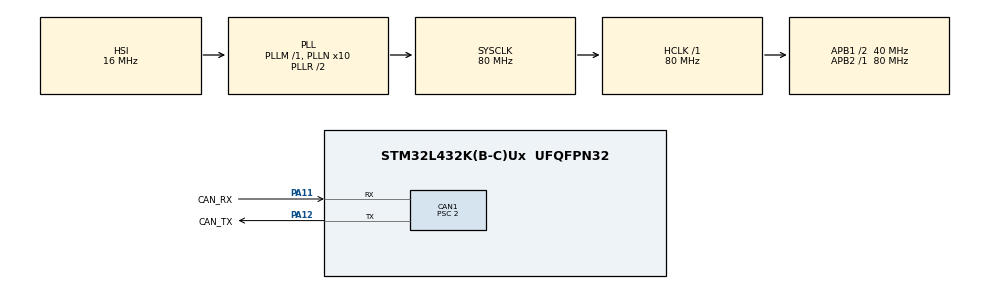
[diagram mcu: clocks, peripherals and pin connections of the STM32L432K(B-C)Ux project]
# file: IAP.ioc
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CAN1.BS1=CAN_BS1_15TQ
CAN1.BS2=CAN_BS2_4TQ
CAN1.CalculateTimeQuantum=50.0
CAN1.Prescaler=2
CAN1.SJW=CAN_SJW_4TQ
CAN1.TXFP=ENABLE
Mcu.Family=STM32L4
Mcu.Name=STM32L432K(B-C)Ux
Mcu.Package=UFQFPN32
NVIC.CAN1_RX0_IRQn=true\:0\:0\:false\:false\:true\:true\:true
NVIC.CAN1_TX_IRQn=true\:0\:0\:false\:false\:true\:true\:true
NVIC.PriorityGroup=NVIC_PRIORITYGROUP_4
PA11.GPIO_Label=CAN_RX
PA11.Mode=Master
PA11.Signal=CAN1_RX
PA12.GPIO_Label=CAN_TX
PA12.Mode=Master
PA12.Signal=CAN1_TX
ProjectManager.HeapSize=0x200
ProjectManager.StackSize=0x400
ProjectManager.TargetToolchain=EWARM V8
RCC.ADCFreq_Value=64000000
RCC.AHBFreq_Value=80000000
RCC.APB1CLKDivider=RCC_HCLK_DIV2
RCC.APB1Freq_Value=40000000
RCC.APB1TimFreq_Value=80000000
RCC.APB2Freq_Value=80000000
RCC.APB2TimFreq_Value=80000000
RCC.CortexFreq_Value=80000000
RCC.HCLKFreq_Value=80000000
RCC.HSE_VALUE=8000000
RCC.HSI48_VALUE=48000000
RCC.HSI_VALUE=16000000
RCC.LSE_VALUE=32768
RCC.MSI_VALUE=4000000
RCC.PLLN=10
RCC.PLLSourceVirtual=RCC_PLLSOURCE_HSI
RCC.SYSCLKFreq_VALUE=80000000
RCC.SYSCLKSource=RCC_SYSCLKSOURCE_PLLCLK
RCC.USBFreq_Value=64000000
RCC.VCOOutputFreq_Value=160000000
board=custom

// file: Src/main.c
/* USER CODE BEGIN Header */
/**
  ******************************************************************************
  * @file           : main.c
  * @brief          : Main program body
  ******************************************************************************
  * @attention
  *
  * <h2><center>&copy; Copyright (c) 2019 STMicroelectronics.
  * All rights reserved.</center></h2>
  *
  * This software component is licensed by ST under BSD 3-Clause license,
  * the "License"; You may not use this file except in compliance with the
  * License. You may obtain a copy of the License at:
  *                        opensource.org/licenses/BSD-3-Clause
  *
  ******************************************************************************
  */
/* USER CODE END Header */

#include "main.h"
#include "can.h"
#include "gpio.h"

/* USER CODE BEGIN Includes */
#include "IAP.h"
/* USER CODE END Includes */

void SystemClock_Config(void);

int main(void)
{
  /* USER CODE BEGIN 1 */
  IAP_Status_Check();

  /* USER CODE END 1 */

  /* MCU Configuration--------------------------------------------------------*/

  /* Reset of all peripherals, Initializes the Flash interface and the Systick. */
  HAL_Init();

  /* Configure the system clock */
  SystemClock_Config();

  /* Initialize all configured peripherals */
  MX_GPIO_Init();
  MX_CAN1_Init();
  /* USER CODE BEGIN 2 */
  IAP_init( &hcan1 );
  CAN_FilterTypeDef FilterConfig;
  FilterConfig.FilterIdHigh = 0xFFFF;
  FilterConfig.FilterIdLow = 0xFFFF;
  FilterConfig.FilterMaskIdHigh = 0x0000;
  FilterConfig.FilterMaskIdLow = 0x0000;
  FilterConfig.FilterFIFOAssignment = CAN_FILTER_FIFO0;
  FilterConfig.FilterBank = 0;
  FilterConfig.FilterMode = CAN_FILTERMODE_IDMASK;
  FilterConfig.FilterScale = CAN_FILTERSCALE_32BIT;
  FilterConfig.FilterActivation = CAN_FILTER_ENABLE;
  if( HAL_CAN_ConfigFilter(&hcan1, &FilterConfig) != HAL_OK )
  {
    Error_Handler();
  }
  HAL_CAN_ActivateNotification( &hcan1, CAN_IT_RX_FIFO0_MSG_PENDING );
  HAL_CAN_Start( &hcan1 );
  /* USER CODE END 2 */

  /* Infinite loop */
  while (1)
  {

  }
}

void SystemClock_Config(void)
{
  RCC_OscInitTypeDef RCC_OscInitStruct = {0};
  RCC_ClkInitTypeDef RCC_ClkInitStruct = {0};

  /** Initializes the CPU, AHB and APB busses clocks
  */
  RCC_OscInitStruct.OscillatorType = RCC_OSCILLATORTYPE_HSI;
  RCC_OscInitStruct.HSIState = RCC_HSI_ON;
  RCC_OscInitStruct.HSICalibrationValue = RCC_HSICALIBRATION_DEFAULT;
  RCC_OscInitStruct.PLL.PLLState = RCC_PLL_ON;
  RCC_OscInitStruct.PLL.PLLSource = RCC_PLLSOURCE_HSI;
  RCC_OscInitStruct.PLL.PLLM = 1;
  RCC_OscInitStruct.PLL.PLLN = 10;
  RCC_OscInitStruct.PLL.PLLP = RCC_PLLP_DIV7;
  RCC_OscInitStruct.PLL.PLLQ = RCC_PLLQ_DIV2;
  RCC_OscInitStruct.PLL.PLLR = RCC_PLLR_DIV2;
  if (HAL_RCC_OscConfig(&RCC_OscInitStruct) != HAL_OK)
  {
    Error_Handler();
  }
  /** Initializes the CPU, AHB and APB busses clocks
  */
  RCC_ClkInitStruct.ClockType = RCC_CLOCKTYPE_HCLK|RCC_CLOCKTYPE_SYSCLK
                              |RCC_CLOCKTYPE_PCLK1|RCC_CLOCKTYPE_PCLK2;
  RCC_ClkInitStruct.SYSCLKSource = RCC_SYSCLKSOURCE_PLLCLK;
  RCC_ClkInitStruct.AHBCLKDivider = RCC_SYSCLK_DIV1;
  RCC_ClkInitStruct.APB1CLKDivider = RCC_HCLK_DIV2;
  RCC_ClkInitStruct.APB2CLKDivider = RCC_HCLK_DIV1;

  if (HAL_RCC_ClockConfig(&RCC_ClkInitStruct, FLASH_LATENCY_4) != HAL_OK)
  {
    Error_Handler();
  }
  /** Configure the main internal regulator output voltage
  */
  if (HAL_PWREx_ControlVoltageScaling(PWR_REGULATOR_VOLTAGE_SCALE1) != HAL_OK)
  {
    Error_Handler();
  }
}

/* USER CODE BEGIN 4 */
void HAL_CAN_RxFifo0MsgPendingCallback( CAN_HandleTypeDef *hcan )
{
    CAN_RxHeaderTypeDef pHeader;
    uint8_t aData[8];
    if( HAL_CAN_GetRxMessage(hcan, CAN_RX_FIFO0, &pHeader, aData) != HAL_OK )
    {
      /* Reception Error */
      Error_Handler();
    }
    if( pHeader.StdId == 0x600 )
    {
      if( IAP_Route_Messages(&pHeader, aData) != HAL_OK );
      {
        /* IAP Error */
        Error_Handler();
      }
    }
}
/* USER CODE END 4 */

void Error_Handler(void)
{
}

/************************ (C) COPYRIGHT STMicroelectronics *****END OF FILE****/
